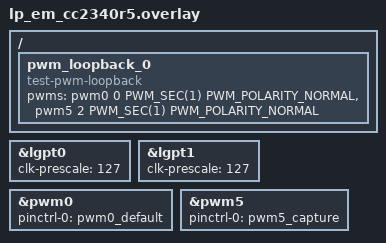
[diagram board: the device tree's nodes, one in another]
/*
 * Copyright (c) 2026 Texas Instruments Incorporated
 *
 * SPDX-License-Identifier: Apache-2.0
 */

/*
 * PWM loopback test overlay for lp_em_cc2340r5 (CC23x0 family).
 *
 * Output:  pwm0 channel 0 -> LGPT0 ch0 -> DIO8 (T0_C0N PFUNC5) -> BoosterPack pin 36
 * Capture: pwm5 channel 2 -> LGPT1 ch2 -> DIO6 (T1_C2  PFUNC3) -> BoosterPack pin 38
 *
 * Wire BoosterPack pin 36 <-> pin 38 to close the loopback.
 *
 * Override clk-prescale to 127 so a 100 ms test period fits in the 16-bit
 * counter: 48 MHz / (127 + 1) = 375 kHz, 100 ms = 37500 cycles.
 */

#include <zephyr/dt-bindings/pwm/pwm.h>

/ {
	pwm_loopback_0 {
		compatible = "test-pwm-loopback";
		pwms = <&pwm0 0 PWM_SEC(1) PWM_POLARITY_NORMAL>,
		       <&pwm5 2 PWM_SEC(1) PWM_POLARITY_NORMAL>;
	};
};

&lgpt0 {
	clk-prescale = <127>;
};

&lgpt1 {
	clk-prescale = <127>;
};

/* LGPT0 ch0 PWM output: DIO8 (T0_C0N) */
&pwm0 {
	status = "okay";
	pinctrl-0 = <&pwm0_default>;
	pinctrl-names = "default";
};

/* LGPT1 ch2 PWM capture input: DIO3 (T1_C2) */
&pwm5 {
	status = "okay";
	pinctrl-0 = <&pwm5_capture>;
	pinctrl-names = "default";
};
